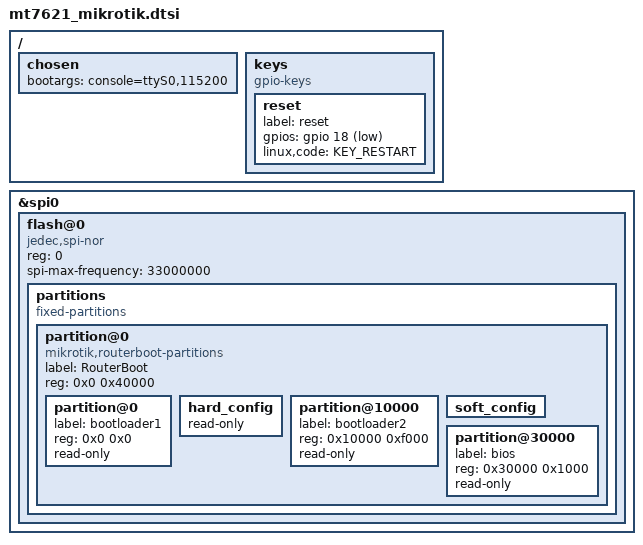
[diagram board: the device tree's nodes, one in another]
// SPDX-License-Identifier: GPL-2.0-or-later OR MIT

#include "mt7621.dtsi"

#include <dt-bindings/input/input.h>
#include <dt-bindings/gpio/gpio.h>

/ {
	chosen {
		bootargs = "console=ttyS0,115200";
	};

	keys: keys {
		compatible = "gpio-keys";

		reset {
			label = "reset";
			gpios = <&gpio 18 GPIO_ACTIVE_LOW>;
			linux,code = <KEY_RESTART>;
		};
	};
};

&spi0 {
	status = "okay";

	flash@0 {
		compatible = "jedec,spi-nor";
		reg = <0>;
		spi-max-frequency = <33000000>;

		partitions: partitions {
			compatible = "fixed-partitions";
			#address-cells = <1>;
			#size-cells = <1>;

			partition@0 {
				label = "RouterBoot";
				reg = <0x0 0x40000>;
				compatible = "mikrotik,routerboot-partitions";
				#address-cells = <1>;
				#size-cells = <1>;

				partition@0 {
					label = "bootloader1";
					reg = <0x0 0x0>;
					read-only;
				};

				hard_config {
					read-only;
				};

				partition@10000 {
					label = "bootloader2";
					reg = <0x10000 0xf000>;
					read-only;
				};

				soft_config {
				};

				partition@30000 {
					label = "bios";
					reg = <0x30000 0x1000>;
					read-only;
				};
			};
		};
	};
};
